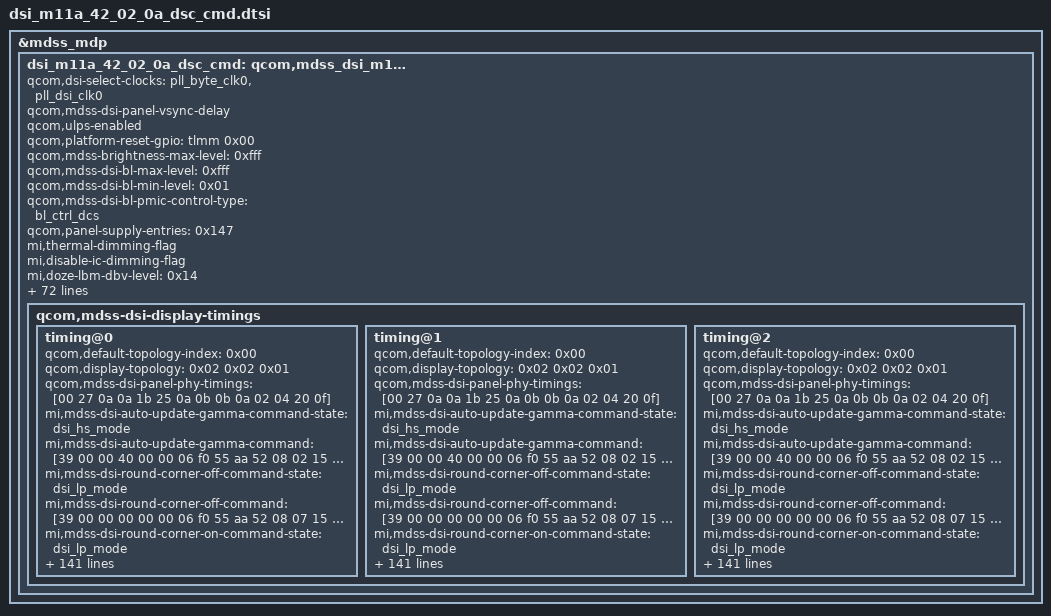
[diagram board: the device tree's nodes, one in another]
&mdss_mdp {
    dsi_m11a_42_02_0a_dsc_cmd: qcom,mdss_dsi_m11a_42_02_0a_dsc_cmd {
        qcom,dsi-select-clocks = "pll_byte_clk0", "pll_dsi_clk0";
        qcom,mdss-dsi-panel-vsync-delay;
        qcom,ulps-enabled;
        qcom,platform-reset-gpio = <&tlmm 0x00 0x00>;
        qcom,mdss-brightness-max-level = <0xfff>;
        qcom,mdss-dsi-bl-max-level = <0xfff>;
        qcom,mdss-dsi-bl-min-level = <0x01>;
        qcom,mdss-dsi-bl-pmic-control-type = "bl_ctrl_dcs";
        qcom,panel-supply-entries = <0x147>;
        mi,thermal-dimming-flag;
        mi,disable-ic-dimming-flag;
        mi,doze-lbm-dbv-level = <0x14>;
        mi,doze-hbm-dbv-level = <0xfc>;
        mi,need-fod-animal-in-normal-enabled;
        mi,fod-low-brightness-lux-threshold = <0x03>;
        mi,fod-low-brightness-clone-threshold = <0xc8>;
        mi,local-hbm-ui-ready-delay-num-frame = <0x04>;
        mi,local-hbm-ctrl-df-reg;
        mi,local-hbm-alpha-ctrl-aa-area;
        mi,local-hbm-white-110nit-update-flag;
        mi,local-hbm-white-1000nit-update-flag;
        mi,local-hbm-enabled;
        mi,mdss-dsi-panel-flatmode-on-status-value = <0x00>;
        mi,mdss-dsi-panel-flatmode-status-read-length = <0x01>;
        mi,mdss-dsi-panel-flatmode-status-read-command-state = "dsi_lp_mode";
        mi,mdss-dsi-panel-flatmode-status-read-command = <0x6010001 0x15f>;
        mi,flatmode-status-check-enabled;
        mi,flat-need-update-several-gamma;
        mi,flat-update-flag;
        mi,ddic-round-corner-enabled;
        mi,hbm-bl-max-level = <0x7ff>;
        mi,hbm-bl-min-level = <0x01>;
        mi,mdss-fac-brightness-max-level = <0x7ff>;
        mi,mdss-dsi-fac-bl-max-level = <0x7ff>;
        mi,normal-max-brightness-clone = <0x1fff>;
        mi,max-brightness-clone = <0x3fff>;
        mi,panel-id = <0x4d313141 0x420200>;
        mi,esd-err-irq-gpio = <&tlmm 0x74 0x2008>;
        qcom,mdss-dsi-dma-schedule-window = <0x32>;
        qcom,mdss-dsi-dma-schedule-line = <0x01>;
        qcom,mdss-dsi-panel-blackness-level = <0xc9e>;
        qcom,mdss-dsi-panel-peak-brightness = <0x401640>;
        qcom,mdss-dsi-panel-hdr-color-primaries = <0x38a4 0x3c8c 0x7d00 0x4268 0x3c8c 0x7530 0x1f40 0xbb8>;
        qcom,mdss-dsi-panel-hdr-enabled;
        qcom,bl-update-flag = "delay_until_first_frame";
        qcom,mdss-dsi-bl-inverted-dbv;
        qcom,mdss-dsi-lp11-init;
        qcom,mdss-dsi-tx-eot-append;
        qcom,mdss-dsi-te-using-te-pin;
        qcom,mdss-dsi-te-check-enable;
        qcom,mdss-dsi-te-dcs-command = <0x01>;
        qcom,mdss-dsi-wr-mem-continue = <0x3c>;
        qcom,mdss-dsi-wr-mem-start = <0x2c>;
        qcom,mdss-dsi-te-pin-select = <0x01>;
        qcom,mdss-pan-physical-height-dimension = <0x609>;
        qcom,mdss-pan-physical-width-dimension = <0x2b7>;
        qcom,mdss-dsi-reset-sequence = <0x01 0x0b 0x00 0x01 0x01 0x0b>;
        qcom,mdss-dsi-mdp-trigger = "none";
        qcom,mdss-dsi-dma-trigger = "trigger_sw";
        qcom,mdss-dsi-lane-3-state;
        qcom,mdss-dsi-lane-2-state;
        qcom,mdss-dsi-lane-1-state;
        qcom,mdss-dsi-lane-0-state;
        qcom,mdss-dsi-bllp-power-mode;
        qcom,mdss-dsi-bllp-eof-power-mode;
        qcom,mdss-dsi-lane-map = "lane_map_0123";
        qcom,mdss-dsi-traffic-mode = "burst_mode";
        qcom,dsi-phy-num = <0x00>;
        qcom,dsi-ctrl-num = <0x00>;
        qcom,mdss-dsi-border-color = <0x00>;
        qcom,mdss-dsi-underflow-color = <0xff>;
        qcom,mdss-dsi-color-order = "rgb_swap_rgb";
        qcom,mdss-dsi-bpp = <0x18>;
        qcom,mdss-dsi-stream = <0x00>;
        qcom,mdss-dsi-virtual-channel-id = <0x00>;
        qcom,mdss-dsi-panel-type = "dsi_cmd_mode";
        qcom,mdss-dsi-panel-name = "xiaomi 42 02 0a cmd mode dsc dsi panel";
    
        qcom,mdss-dsi-display-timings {
    
            timing@0 {
                qcom,default-topology-index = <0x00>;
                qcom,display-topology = <0x02 0x02 0x01>;
                qcom,mdss-dsi-panel-phy-timings = [00 27 0a 0a 1b 25 0a 0b 0b 0a 02 04 20 0f];
                mi,mdss-dsi-auto-update-gamma-command-state = "dsi_hs_mode";
                mi,mdss-dsi-auto-update-gamma-command = [39 00 00 40 00 00 06 f0 55 aa 52 08 02 15 00 00 00 00 00 02 cc 00];
                mi,mdss-dsi-round-corner-off-command-state = "dsi_lp_mode";
                mi,mdss-dsi-round-corner-off-command = [39 00 00 00 00 00 06 f0 55 aa 52 08 07 15 00 00 00 00 00 02 c0 b0];
                mi,mdss-dsi-round-corner-on-command-state = "dsi_lp_mode";
                mi,mdss-dsi-round-corner-on-command = [39 00 00 00 00 00 06 f0 55 aa 52 08 07 15 00 00 00 00 00 02 c0 b1];
                mi,mdss-dsi-local-hbm-off-to-hbm-command-state = "dsi_hs_mode";
                mi,mdss-dsi-local-hbm-off-to-hbm-command-update = <0x51 0x02 0x02>;
                mi,mdss-dsi-local-hbm-off-to-hbm-command = [39 00 00 40 00 00 06 f0 55 aa 52 08 02 15 00 00 00 00 00 02 cc 00 39 00 00 40 00 00 03 51 07 ff 39 00 00 40 00 00 02 86 00 39 00 00 00 00 00 02 87 20];
                mi,mdss-dsi-local-hbm-off-to-normal-command-state = "dsi_hs_mode";
                mi,mdss-dsi-local-hbm-off-to-normal-command-update = <0x51 0x02 0x02>;
                mi,mdss-dsi-local-hbm-off-to-normal-command = [39 00 00 40 00 00 06 f0 55 aa 52 08 02 15 00 00 00 00 00 02 cc 00 39 00 00 40 00 00 03 51 07 ff 39 00 00 40 00 00 02 86 00 39 00 00 00 00 00 02 87 20];
                mi,mdss-dsi-local-hbm-normal-green-500nit-command-state = "dsi_lp_mode";
                mi,mdss-dsi-local-hbm-normal-green-500nit-command-update = <0x87 0x1d 0x02 0xd0 0x1b 0x06 0xdf 0x19 0x02>;
                mi,mdss-dsi-local-hbm-normal-green-500nit-command = [39 00 00 40 00 00 06 f0 55 aa 52 08 02 15 00 00 00 00 00 02 cc 00 39 00 00 40 00 00 06 f0 55 aa 52 08 07 39 00 00 40 00 00 02 c0 b1 39 00 00 40 00 00 06 f0 55 aa 52 08 00 39 00 00 40 00 00 04 df 45 00 00 39 00 00 40 00 00 02 6f 13 39 00 00 40 00 00 05 df 02 d0 0b 42 39 00 00 40 00 00 02 6f 1b 39 00 00 40 00 00 05 df 02 54 0a c6 39 00 00 40 00 00 02 6f 1f 39 00 00 40 00 00 05 df 03 4c 0b be 39 00 00 40 00 00 02 6f 2b 39 00 00 40 00 00 07 df 3f ff 3f ff 3f ff 39 00 00 40 00 00 02 6f 32 39 00 00 40 00 00 07 df 00 00 13 00 00 00 39 00 00 40 00 00 02 6f 38 39 00 00 40 00 00 03 df 00 40 39 00 00 40 00 00 02 6f 88 39 00 00 40 00 00 02 df 40 39 00 00 40 00 00 02 6f 00 39 00 00 40 00 00 06 88 01 02 d0 0b 44 39 00 00 40 00 00 02 53 20 39 00 00 40 00 00 06 f0 55 aa 52 08 00 39 00 00 40 00 00 02 6f 4c 39 00 00 40 00 00 03 df 05 1c 39 00 00 40 00 00 06 f0 55 aa 52 08 02 39 00 00 40 00 00 07 d0 00 00 09 1a 00 00 39 00 00 40 00 00 02 6f 01 39 00 00 40 00 00 03 87 0d ff 39 00 00 40 00 00 02 87 21 39 00 00 00 00 00 02 85 00];
                mi,mdss-dsi-local-hbm-normal-white-110nit-command-state = "dsi_hs_mode";
                mi,mdss-dsi-local-hbm-normal-white-110nit-command-update = <0x87 0x1d 0x03 0xd0 0x1b 0x06>;
                mi,mdss-dsi-local-hbm-normal-white-110nit-command = [39 00 00 40 00 00 06 f0 55 aa 52 08 02 15 00 00 00 00 00 02 cc 00 39 00 00 40 00 00 06 f0 55 aa 52 08 07 39 00 00 40 00 00 02 c0 b1 39 00 00 40 00 00 06 f0 55 aa 52 08 00 39 00 00 40 00 00 04 df 45 00 00 39 00 00 40 00 00 02 6f 13 39 00 00 40 00 00 05 df 02 d0 0b 42 39 00 00 40 00 00 02 6f 1b 39 00 00 40 00 00 05 df 02 54 0a c6 39 00 00 40 00 00 02 6f 1f 39 00 00 40 00 00 05 df 03 4c 0b be 39 00 00 40 00 00 02 6f 2b 39 00 00 40 00 00 07 df 3f ff 3f ff 3f ff 39 00 00 40 00 00 02 6f 32 39 00 00 40 00 00 07 df 00 00 13 00 00 00 39 00 00 40 00 00 02 6f 38 39 00 00 40 00 00 03 df 00 40 39 00 00 40 00 00 02 6f 88 39 00 00 40 00 00 02 df 40 39 00 00 40 00 00 02 6f 00 39 00 00 40 00 00 06 88 01 02 d0 0b 44 39 00 00 40 00 00 02 53 20 39 00 00 40 00 00 06 f0 55 aa 52 08 00 39 00 00 40 00 00 02 6f 4c 39 00 00 40 00 00 03 df 05 1c 39 00 00 40 00 00 06 f0 55 aa 52 08 02 39 00 00 40 00 00 07 d0 08 00 07 26 08 7f 39 00 00 40 00 00 02 6f 01 39 00 00 40 00 00 03 87 0d ff 39 00 00 40 00 00 02 87 21 39 00 00 00 00 00 02 85 00];
                mi,mdss-dsi-local-hbm-hlpm-white-110nit-command-state = "dsi_hs_mode";
                mi,mdss-dsi-local-hbm-hlpm-white-110nit-command-update = <0x51 0x02 0x02 0x87 0x26 0x03 0xd0 0x24 0x06>;
                mi,mdss-dsi-local-hbm-hlpm-white-110nit-command = [39 00 00 40 00 00 06 f0 55 aa 52 08 02 15 00 00 40 00 00 02 cc 00 39 00 00 00 00 00 03 51 00 00 39 00 00 40 00 00 06 f0 55 aa 52 08 01 15 00 00 40 00 00 02 6f 02 15 00 00 40 00 00 02 b0 08 15 00 00 40 00 00 02 e4 80 15 00 00 40 00 00 02 6f 0a 15 00 00 40 00 00 02 e4 80 15 00 00 40 00 00 02 65 00 15 00 00 00 2a 00 02 38 00 39 00 00 40 00 00 06 f0 55 aa 52 08 07 15 00 00 40 00 00 02 c0 b1 39 00 00 40 00 00 06 f0 55 aa 52 08 00 39 00 00 40 00 00 04 df 45 00 00 15 00 00 40 00 00 02 6f 13 39 00 00 40 00 00 05 df 02 d0 0b 42 15 00 00 40 00 00 02 6f 1b 39 00 00 40 00 00 05 df 02 54 0a c6 15 00 00 40 00 00 02 6f 1f 39 00 00 40 00 00 05 df 03 4c 0b be 15 00 00 40 00 00 02 6f 2b 39 00 00 40 00 00 07 df 3f ff 3f ff 3f ff 15 00 00 40 00 00 02 6f 32 39 00 00 40 00 00 07 df 00 00 13 00 00 00 15 00 00 40 00 00 02 6f 38 39 00 00 40 00 00 03 df 00 40 15 00 00 40 00 00 02 6f 88 15 00 00 40 00 00 02 df 40 15 00 00 40 00 00 02 6f 00 39 00 00 40 00 00 06 88 01 02 d0 0b 44 15 00 00 40 00 00 02 53 20 39 00 00 40 00 00 06 f0 55 aa 52 08 00 15 00 00 40 00 00 02 6f 4c 39 00 00 40 00 00 03 df 05 1c 39 00 00 40 00 00 06 f0 55 aa 52 08 02 39 00 00 40 00 00 07 d0 08 00 07 26 08 7f 15 00 00 40 00 00 02 6f 01 39 00 00 40 00 00 03 87 0d ff 15 00 00 40 00 00 02 87 21 15 00 00 00 00 00 02 85 00];
                mi,mdss-dsi-local-hbm-normal-white-1000nit-command-state = "dsi_hs_mode";
                mi,mdss-dsi-local-hbm-normal-white-1000nit-command-update = <0x87 0x1d 0x02 0xd0 0x1b 0x06 0xdf 0x19 0x02>;
                mi,mdss-dsi-local-hbm-normal-white-1000nit-command = [39 00 00 40 00 00 06 f0 55 aa 52 08 02 15 00 00 00 00 00 02 cc 00 39 00 00 40 00 00 06 f0 55 aa 52 08 07 39 00 00 40 00 00 02 c0 b1 39 00 00 40 00 00 06 f0 55 aa 52 08 00 39 00 00 40 00 00 04 df 45 00 00 39 00 00 40 00 00 02 6f 13 39 00 00 40 00 00 05 df 02 d0 0b 42 39 00 00 40 00 00 02 6f 1b 39 00 00 40 00 00 05 df 02 54 0a c6 39 00 00 40 00 00 02 6f 1f 39 00 00 40 00 00 05 df 03 4c 0b be 39 00 00 40 00 00 02 6f 2b 39 00 00 40 00 00 07 df 3f ff 3f ff 3f ff 39 00 00 40 00 00 02 6f 32 39 00 00 40 00 00 07 df 00 00 13 00 00 00 39 00 00 40 00 00 02 6f 38 39 00 00 40 00 00 03 df 00 40 39 00 00 40 00 00 02 6f 88 39 00 00 40 00 00 02 df 40 39 00 00 40 00 00 02 6f 00 39 00 00 40 00 00 06 88 01 02 d0 0b 44 39 00 00 40 00 00 02 53 20 39 00 00 40 00 00 06 f0 55 aa 52 08 00 39 00 00 40 00 00 02 6f 4c 39 00 00 40 00 00 03 df 05 1c 39 00 00 40 00 00 06 f0 55 aa 52 08 02 39 00 00 40 00 00 07 d0 0b 06 09 97 0b 69 39 00 00 40 00 00 02 6f 01 39 00 00 40 00 00 03 87 0d ff 39 00 00 40 00 00 02 87 21 39 00 00 00 00 00 02 85 00];
                mi,mdss-dsi-local-hbm-hlpm-white-1000nit-command-state = "dsi_hs_mode";
                mi,mdss-dsi-local-hbm-hlpm-white-1000nit-command-update = <0x51 0x02 0x02 0x87 0x26 0x02 0xd0 0x24 0x06 0xdf 0x22 0x02>;
                mi,mdss-dsi-local-hbm-hlpm-white-1000nit-command = [39 00 00 40 00 00 06 f0 55 aa 52 08 02 15 00 00 40 00 00 02 cc 00 39 00 00 00 00 00 03 51 00 00 39 00 00 40 00 00 06 f0 55 aa 52 08 01 15 00 00 40 00 00 02 6f 02 15 00 00 40 00 00 02 b0 08 15 00 00 40 00 00 02 e4 80 15 00 00 40 00 00 02 6f 0a 15 00 00 40 00 00 02 e4 80 15 00 00 40 00 00 02 65 00 15 00 00 00 2a 00 02 38 00 39 00 00 40 00 00 06 f0 55 aa 52 08 07 15 00 00 40 00 00 02 c0 b1 39 00 00 40 00 00 06 f0 55 aa 52 08 00 39 00 00 40 00 00 04 df 45 00 00 15 00 00 40 00 00 02 6f 13 39 00 00 40 00 00 05 df 02 d0 0b 42 15 00 00 40 00 00 02 6f 1b 39 00 00 40 00 00 05 df 02 54 0a c6 15 00 00 40 00 00 02 6f 1f 39 00 00 40 00 00 05 df 03 4c 0b be 15 00 00 40 00 00 02 6f 2b 39 00 00 40 00 00 07 df 3f ff 3f ff 3f ff 15 00 00 40 00 00 02 6f 32 39 00 00 40 00 00 07 df 00 00 13 00 00 00 15 00 00 40 00 00 02 6f 38 39 00 00 40 00 00 03 df 00 40 15 00 00 40 00 00 02 6f 88 15 00 00 40 00 00 02 df 40 15 00 00 40 00 00 02 6f 00 39 00 00 40 00 00 06 88 01 02 d0 0b 44 15 00 00 40 00 00 02 53 20 39 00 00 40 00 00 06 f0 55 aa 52 08 00 15 00 00 40 00 00 02 6f 4c 39 00 00 40 00 00 03 df 05 1c 39 00 00 40 00 00 06 f0 55 aa 52 08 02 39 00 00 40 00 00 07 d0 0b 06 09 97 0b 69 15 00 00 40 00 00 02 6f 01 39 00 00 40 00 00 03 87 0d ff 15 00 00 40 00 00 02 87 21 15 00 00 00 00 00 02 85 00];
                mi,mdss-dsi-hbm-fod-off-command-update = <0x51 0x00 0x02>;
                mi,mdss-dsi-hbm-fod-off-command-state = "dsi_lp_mode";
                mi,mdss-dsi-hbm-fod-off-command = <0x39000040 0x6f0 0x55aa5208 0x2150000 0x02 0xcc003900 0x00 0x35107ff>;
                mi,mdss-dsi-hbm-fod-on-command-state = "dsi_lp_mode";
                mi,mdss-dsi-hbm-fod-on-command = <0x39000040 0x6f0 0x55aa5208 0x2150000 0x02 0xcc003900 0x00 0x3510fff>;
                mi,mdss-dsi-local-hbm-off-to-llpm-command-state = "dsi_hs_mode";
                mi,mdss-dsi-local-hbm-off-to-llpm-command = [39 00 00 40 00 00 06 f0 55 aa 52 08 02 15 00 00 00 00 00 02 cc 00 39 00 00 40 00 00 03 51 07 ff 39 00 00 40 00 00 02 86 00 39 00 00 00 00 00 02 87 20 39 00 00 40 00 00 06 f0 55 aa 52 08 00 15 00 00 40 00 00 02 6f 01 15 00 00 00 00 00 02 be 41 39 00 00 40 00 00 07 51 00 00 00 00 01 55 39 00 00 40 00 00 06 f0 55 aa 52 08 01 39 00 00 40 00 00 02 6f 02 39 00 00 40 00 00 02 b0 00 39 00 00 40 00 00 02 e4 90 39 00 00 40 00 00 02 6f 0a 39 00 00 40 00 00 02 e4 90 39 00 00 40 00 00 02 39 00 39 00 00 00 00 00 02 65 01];
                mi,mdss-dsi-local-hbm-off-to-hlpm-command-state = "dsi_hs_mode";
                mi,mdss-dsi-local-hbm-off-to-hlpm-command = [39 00 00 40 00 00 06 f0 55 aa 52 08 02 15 00 00 00 00 00 02 cc 00 39 00 00 40 00 00 03 51 07 ff 39 00 00 40 00 00 02 86 00 39 00 00 00 00 00 02 87 20 39 00 00 40 00 00 06 f0 55 aa 52 08 00 15 00 00 40 00 00 02 6f 01 15 00 00 00 00 00 02 be 41 39 00 00 40 00 00 07 51 00 00 00 00 0f ff 39 00 00 40 00 00 06 f0 55 aa 52 08 01 39 00 00 40 00 00 02 6f 02 39 00 00 40 00 00 02 b0 00 39 00 00 40 00 00 02 e4 90 39 00 00 40 00 00 02 6f 0a 39 00 00 40 00 00 02 e4 90 39 00 00 40 00 00 02 39 00 39 00 00 00 00 00 02 65 01];
                mi,mdss-dsi-doze-lbm-nolp-command-state = "dsi_hs_mode";
                mi,mdss-dsi-doze-lbm-nolp-command = [39 00 00 40 00 00 06 f0 55 aa 52 08 02 15 00 00 00 00 00 02 cc 00 39 00 00 40 00 00 03 51 00 14 39 00 00 40 00 00 06 f0 55 aa 52 08 01 15 00 00 40 00 00 02 6f 02 15 00 00 40 00 00 02 b0 08 15 00 00 40 00 00 02 e4 80 15 00 00 40 00 00 02 6f 0a 15 00 00 40 00 00 02 e4 80 15 00 00 40 00 00 02 65 00 05 00 00 00 00 00 01 38 39 00 00 40 00 00 06 f0 55 aa 52 08 00 39 00 00 40 00 00 02 6f 01 39 00 00 00 00 00 02 be 45];
                mi,mdss-dsi-doze-hbm-nolp-command-state = "dsi_hs_mode";
                mi,mdss-dsi-doze-hbm-nolp-command = [39 00 00 40 00 00 06 f0 55 aa 52 08 02 15 00 00 00 00 00 02 cc 00 39 00 00 40 00 00 03 51 00 fc 39 00 00 40 00 00 06 f0 55 aa 52 08 01 15 00 00 40 00 00 02 6f 02 15 00 00 40 00 00 02 b0 08 15 00 00 40 00 00 02 e4 80 15 00 00 40 00 00 02 6f 0a 15 00 00 40 00 00 02 e4 80 15 00 00 40 00 00 02 65 00 05 00 00 00 00 00 01 38 39 00 00 40 00 00 06 f0 55 aa 52 08 00 39 00 00 40 00 00 02 6f 01 39 00 00 00 00 00 02 be 45];
                mi,mdss-dsi-doze-lbm-command-state = "dsi_hs_mode";
                mi,mdss-dsi-doze-lbm-command = [39 00 00 40 00 00 06 f0 55 aa 52 08 02 15 00 00 00 00 00 02 cc 00 39 00 00 40 00 00 06 f0 55 aa 52 08 00 15 00 00 40 00 00 02 6f 01 15 00 00 00 00 00 02 be 41 39 00 00 40 00 00 07 51 00 00 00 00 01 55 39 00 00 40 00 00 06 f0 55 aa 52 08 01 15 00 00 40 00 00 02 6f 02 15 00 00 40 00 00 02 b0 00 15 00 00 40 00 00 02 e4 90 15 00 00 40 00 00 02 6f 0a 15 00 00 40 00 00 02 e4 90 05 00 00 40 00 00 01 39 15 00 00 00 00 00 02 65 01];
                mi,mdss-dsi-doze-hbm-command-state = "dsi_hs_mode";
                mi,mdss-dsi-doze-hbm-command = [39 00 00 40 00 00 06 f0 55 aa 52 08 02 15 00 00 00 00 00 02 cc 00 39 00 00 40 00 00 06 f0 55 aa 52 08 00 15 00 00 40 00 00 02 6f 01 15 00 00 00 00 00 02 be 41 39 00 00 40 00 00 07 51 00 00 00 00 0f ff 39 00 00 40 00 00 06 f0 55 aa 52 08 01 15 00 00 40 00 00 02 6f 02 15 00 00 40 00 00 02 b0 00 15 00 00 40 00 00 02 e4 90 15 00 00 40 00 00 02 6f 0a 15 00 00 40 00 00 02 e4 90 05 00 00 40 00 00 01 39 15 00 00 00 00 00 02 65 01];
                mi,mdss-dsi-flat-mode-off-sec-command-state = "dsi_hs_mode";
                mi,mdss-dsi-flat-mode-off-sec-command = [39 00 00 40 00 00 06 f0 55 aa 52 08 02 15 00 00 00 00 00 02 cc 00];
                mi,mdss-dsi-flat-mode-off-command-state = "dsi_hs_mode";
                mi,mdss-dsi-flat-mode-off-command = <0x15000040 0x22f 0x2150000 0x40000002 0x5f011500 0x400000 0x2260015 0x4000 0x28b00 0x39000040 0x6f0 0x55aa5208 0x150000 0x40000002 0x6f031500 0x400000 0x2c01015 0x4000 0x26f31 0x15000040 0x2df 0x21390000 0x40000006 0xf055aa52 0x8021500 0x400000 0x2cc3015 0x14 0x2ce01>;
                mi,mdss-dsi-flat-mode-on-sec-command-state = "dsi_hs_mode";
                mi,mdss-dsi-flat-mode-on-sec-command = [39 00 00 40 00 00 06 f0 55 aa 52 08 02 15 00 00 00 00 00 02 cc 00];
                mi,mdss-dsi-flat-mode-on-command-state = "dsi_hs_mode";
                mi,mdss-dsi-flat-mode-on-command = <0x15000040 0x22f 0x2150000 0x40000002 0x5f001500 0x400000 0x2260215 0x4000 0x28b00 0x39000040 0x6f0 0x55aa5208 0x150000 0x40000002 0x6f031500 0x400000 0x2c03215 0x4000 0x26f31 0x15000040 0x2df 0x23390000 0x40000006 0xf055aa52 0x8021500 0x400000 0x2cc3015 0x14 0x2ce01>;
                mi,mdss-flat-status-control-lhbm-gamma-cfg = <0x23 0x21>;
                mi,mdss-flat-status-control-gamma-cfg = <0x32 0x10>;
                qcom,mdss-dsc-block-prediction-enable;
                qcom,mdss-dsc-bit-per-pixel = <0x08>;
                qcom,mdss-dsc-bit-per-component = <0x0a>;
                qcom,mdss-dsc-slice-per-pkt = <0x02>;
                qcom,mdss-dsc-slice-width = <0x2d0>;
                qcom,mdss-dsc-slice-height = <0x20>;
                qcom,mdss-dsc-scr-version = <0x00>;
                qcom,mdss-dsc-version = <0x12>;
                qcom,compression-mode = "dsc";
                qcom,mdss-dsi-nolp-command-state = "dsi_hs_mode";
                qcom,mdss-dsi-nolp-command = [39 00 00 40 00 00 06 f0 55 aa 52 08 02 15 00 00 00 00 00 02 cc 00 39 00 00 40 00 00 03 51 00 00 39 00 00 40 00 00 06 f0 55 aa 52 08 01 15 00 00 40 00 00 02 6f 02 15 00 00 40 00 00 02 b0 08 15 00 00 40 00 00 02 e4 80 15 00 00 40 00 00 02 6f 0a 15 00 00 40 00 00 02 e4 80 15 00 00 40 00 00 02 65 00 05 00 00 00 00 00 01 38 39 00 00 40 00 00 06 f0 55 aa 52 08 00 39 00 00 40 00 00 02 6f 01 39 00 00 00 00 00 02 be 45];
                qcom,mdss-dsi-timing-switch-command-state = "dsi_hs_mode";
                qcom,mdss-dsi-timing-switch-command-update = <0xc0 0x04 0x01 0xdf 0x06 0x01>;
                qcom,mdss-dsi-timing-switch-command = [15 00 00 40 00 00 02 2f 02 15 00 00 40 00 00 02 8b 00 39 00 00 40 00 00 06 f0 55 aa 52 08 00 15 00 00 40 00 00 02 6f 03 15 00 00 40 00 00 02 c0 10 15 00 00 40 00 00 02 6f 31 15 00 00 40 00 00 02 df 21 39 00 00 40 00 00 06 f0 55 aa 52 08 02 15 00 00 40 00 00 02 cc 30 15 00 00 00 00 00 02 ce 01];
                qcom,mdss-dsi-off-command-state = "dsi_lp_mode";
                qcom,mdss-dsi-on-command-state = "dsi_lp_mode";
                qcom,mdss-dsi-off-command = [39 00 00 00 14 00 02 28 00 39 00 00 00 64 00 02 10 00];
                qcom,mdss-dsi-on-command = [39 00 00 40 00 00 06 f0 55 aa 52 08 00 15 00 00 40 00 00 02 6f 1a 15 00 00 00 00 00 02 c2 00 39 00 00 40 00 00 06 f0 55 aa 52 08 01 15 00 00 40 00 00 02 6f 0e 15 00 00 40 00 00 02 b4 1f 39 00 00 40 00 00 05 ff aa 55 a5 80 15 00 00 40 00 00 02 6f 02 15 00 00 00 00 00 02 f5 10 39 00 00 40 00 00 06 f0 55 aa 52 08 01 39 00 00 00 00 00 03 b1 06 06 39 00 00 40 00 00 06 f0 55 aa 52 08 01 15 00 00 40 00 00 02 6f 01 15 00 00 40 00 00 02 c4 e3 39 00 00 40 00 00 05 ff aa 55 a5 80 15 00 00 40 00 00 02 6f 18 15 00 00 00 00 00 02 f8 19 39 00 00 40 00 00 06 f0 55 aa 52 08 01 15 00 00 40 00 00 02 6f 01 39 00 00 00 00 00 04 c5 0b 0b 0b 39 00 00 40 00 00 06 f0 55 aa 52 08 04 15 00 00 00 00 00 02 c0 20 39 00 00 40 00 00 06 f0 55 aa 52 08 00 15 00 00 40 00 00 02 6f 20 39 00 00 40 00 00 09 c6 55 55 55 55 55 55 55 55 39 00 00 40 00 00 05 ff aa 55 a5 80 15 00 00 40 00 00 02 6f 1b 15 00 00 40 00 00 02 f4 55 15 00 00 40 00 00 02 6f 19 15 00 00 00 00 00 02 f2 00 39 00 00 40 00 00 05 ff aa 55 a5 81 15 00 00 40 00 00 02 6f 18 15 00 00 00 00 00 02 fb 04 39 00 00 40 00 00 05 ff aa 55 a5 81 15 00 00 40 00 00 02 6f 07 15 00 00 00 00 00 02 fc 08 39 00 00 40 00 00 05 2a 00 00 05 9f 39 00 00 00 00 00 05 2b 00 00 0c 7f 15 00 00 40 00 00 02 90 03 39 00 00 00 00 00 13 91 ab a8 00 20 d2 00 02 86 03 5e 00 0a 03 5b 02 63 10 f0 15 00 00 40 00 00 02 35 00 15 00 00 00 00 00 02 5a 01 39 00 00 40 00 00 06 f0 55 aa 52 08 01 39 00 00 40 00 00 06 d2 00 00 00 00 15 15 00 00 40 00 00 02 6f 05 39 00 00 40 00 00 04 d2 01 00 00 15 00 00 40 00 00 02 6f 0e 39 00 00 40 00 00 06 d2 00 00 10 13 32 39 00 00 40 00 00 0b e4 80 03 00 00 00 00 00 00 00 33 15 00 00 40 00 00 02 6f 0a 39 00 00 00 00 00 07 e4 80 03 00 10 00 53 39 00 00 40 00 00 05 3b 00 18 00 10 15 00 00 40 00 00 02 53 20 39 00 00 40 00 00 07 51 00 00 0f ff 0f ff 15 00 00 40 00 00 02 9c 01 15 00 00 00 00 00 02 2c 00 15 00 00 40 00 00 02 2f 02 15 00 00 40 00 00 02 5f 01 15 00 00 40 00 00 02 26 00 15 00 00 40 00 00 02 8b 00 39 00 00 40 00 00 06 f0 55 aa 52 08 00 15 00 00 40 00 00 02 6f 03 15 00 00 40 00 00 02 c0 10 15 00 00 40 00 00 02 6f 31 15 00 00 40 00 00 02 df 21 39 00 00 40 00 00 06 f0 55 aa 52 08 02 15 00 00 40 00 00 02 cc 30 15 00 00 40 14 00 02 ce 01 15 00 00 00 00 00 02 cc 00 39 00 00 40 00 00 06 f0 55 aa 52 08 01 39 00 00 40 00 00 0c c3 90 04 20 13 ff 00 04 20 0e ff 00 15 00 00 40 00 00 02 6f 0b 39 00 00 40 00 00 07 c3 06 30 1d 06 67 14 15 00 00 40 00 00 02 6f 11 39 00 00 40 00 00 07 c3 06 30 1d 06 67 14 15 00 00 40 00 00 02 6f 17 39 00 00 40 00 00 07 c3 06 30 1d 06 67 14 15 00 00 40 00 00 02 6f 1d 39 00 00 40 00 00 07 c3 06 30 1d 06 67 14 15 00 00 40 00 00 02 6f 23 39 00 00 00 00 00 07 c3 06 30 1d 06 67 14 39 00 00 40 00 00 06 f0 55 aa 52 08 00 15 00 00 40 00 00 02 6f 01 15 00 00 00 00 00 02 be 45 15 00 00 40 00 00 02 6f 05 15 00 00 00 00 00 02 be 88 39 00 00 40 00 00 06 f0 55 aa 52 08 00 15 00 00 40 00 00 02 6f 07 39 00 00 40 00 00 05 b5 2a 1e 00 32 39 00 00 40 00 00 1a b7 40 40 41 42 43 44 45 46 47 48 49 4a 4b 4c 4d 4e 4f 50 51 51 51 51 51 51 51 15 00 00 40 00 00 02 6f 19 39 00 00 40 00 00 0d b7 17 88 99 aa bb cc dd ee ff ff ff ff 15 00 00 40 00 00 02 6f 25 39 00 00 00 00 00 19 b7 ba ff 77 ef 67 df 57 cf 47 bf 37 af 27 9f 17 8f 07 7f ff ff ff ff ff ff 39 00 00 40 00 00 06 f0 55 aa 52 08 07 15 00 00 00 00 00 02 c0 b1 05 00 00 00 78 00 02 11 00 05 00 00 00 00 00 02 29 00 39 00 00 40 00 00 06 f0 55 aa 52 08 04 15 00 00 40 00 00 02 6f 16 15 00 00 40 00 00 02 d2 19 15 00 00 40 00 00 02 6f 16 15 00 00 40 00 00 02 d4 18 15 00 00 40 00 00 02 6f 2f 15 00 00 40 00 00 02 d2 28 15 00 00 40 00 00 02 6f 2f 15 00 00 40 00 00 02 d4 27 15 00 00 40 00 00 02 6f 48 15 00 00 40 00 00 02 d2 18 15 00 00 40 00 00 02 6f 48 15 00 00 00 00 00 02 d4 17];
                qcom,mdss-mdp-transfer-time-us = <0x1c84>;
                qcom,mdss-dsi-panel-jitter = <0x05 0x01>;
                qcom,mdss-dsi-panel-clockrate = <0x47868c00>;
                qcom,mdss-dsi-v-bottom-border = <0x00>;
                qcom,mdss-dsi-v-top-border = <0x00>;
                qcom,mdss-dsi-h-right-border = <0x00>;
                qcom,mdss-dsi-h-left-border = <0x00>;
                qcom,mdss-dsi-h-sync-pulse = <0x00>;
                qcom,mdss-dsi-v-pulse-width = <0x0e>;
                qcom,mdss-dsi-v-front-porch = <0x10>;
                qcom,mdss-dsi-v-back-porch = <0x06>;
                qcom,mdss-dsi-h-sync-skew = <0x00>;
                qcom,mdss-dsi-h-pulse-width = <0x0c>;
                qcom,mdss-dsi-h-back-porch = <0x08>;
                qcom,mdss-dsi-h-front-porch = <0x08>;
                qcom,mdss-dsi-panel-height = <0xc80>;
                qcom,mdss-dsi-panel-width = <0x5a0>;
                qcom,mdss-dsi-panel-framerate = <0x3c>;
                qcom,mdss-dsi-cmd-mode;
            };
    
            timing@1 {
                qcom,default-topology-index = <0x00>;
                qcom,display-topology = <0x02 0x02 0x01>;
                qcom,mdss-dsi-panel-phy-timings = [00 27 0a 0a 1b 25 0a 0b 0b 0a 02 04 20 0f];
                mi,mdss-dsi-auto-update-gamma-command-state = "dsi_hs_mode";
                mi,mdss-dsi-auto-update-gamma-command = [39 00 00 40 00 00 06 f0 55 aa 52 08 02 15 00 00 00 00 00 02 cc 00];
                mi,mdss-dsi-round-corner-off-command-state = "dsi_lp_mode";
                mi,mdss-dsi-round-corner-off-command = [39 00 00 00 00 00 06 f0 55 aa 52 08 07 15 00 00 00 00 00 02 c0 b0];
                mi,mdss-dsi-round-corner-on-command-state = "dsi_lp_mode";
                mi,mdss-dsi-round-corner-on-command = [39 00 00 00 00 00 06 f0 55 aa 52 08 07 15 00 00 00 00 00 02 c0 b1];
                mi,mdss-dsi-local-hbm-off-to-hbm-command-state = "dsi_hs_mode";
                mi,mdss-dsi-local-hbm-off-to-hbm-command-update = <0x51 0x02 0x02>;
                mi,mdss-dsi-local-hbm-off-to-hbm-command = [39 00 00 40 00 00 06 f0 55 aa 52 08 02 15 00 00 00 00 00 02 cc 00 39 00 00 40 00 00 03 51 07 ff 39 00 00 40 00 00 02 86 00 39 00 00 00 00 00 02 87 20];
                mi,mdss-dsi-local-hbm-off-to-normal-command-state = "dsi_hs_mode";
                mi,mdss-dsi-local-hbm-off-to-normal-command-update = <0x51 0x02 0x02>;
                mi,mdss-dsi-local-hbm-off-to-normal-command = [39 00 00 40 00 00 06 f0 55 aa 52 08 02 15 00 00 00 00 00 02 cc 00 39 00 00 40 00 00 03 51 07 ff 39 00 00 40 00 00 02 86 00 39 00 00 00 00 00 02 87 20];
                mi,mdss-dsi-local-hbm-normal-green-500nit-command-state = "dsi_lp_mode";
                mi,mdss-dsi-local-hbm-normal-green-500nit-command-update = <0x87 0x1d 0x02 0xd0 0x1b 0x06 0xdf 0x19 0x02>;
                mi,mdss-dsi-local-hbm-normal-green-500nit-command = [39 00 00 40 00 00 06 f0 55 aa 52 08 02 15 00 00 00 00 00 02 cc 00 39 00 00 40 00 00 06 f0 55 aa 52 08 07 39 00 00 40 00 00 02 c0 b1 39 00 00 40 00 00 06 f0 55 aa 52 08 00 39 00 00 40 00 00 04 df 45 00 00 39 00 00 40 00 00 02 6f 13 39 00 00 40 00 00 05 df 02 d0 0b 42 39 00 00 40 00 00 02 6f 1b 39 00 00 40 00 00 05 df 02 54 0a c6 39 00 00 40 00 00 02 6f 1f 39 00 00 40 00 00 05 df 03 4c 0b be 39 00 00 40 00 00 02 6f 2b 39 00 00 40 00 00 07 df 3f ff 3f ff 3f ff 39 00 00 40 00 00 02 6f 32 39 00 00 40 00 00 07 df 00 00 13 00 00 00 39 00 00 40 00 00 02 6f 38 39 00 00 40 00 00 03 df 00 40 39 00 00 40 00 00 02 6f 88 39 00 00 40 00 00 02 df 40 39 00 00 40 00 00 02 6f 00 39 00 00 40 00 00 06 88 01 02 d0 0b 44 39 00 00 40 00 00 02 53 20 39 00 00 40 00 00 06 f0 55 aa 52 08 00 39 00 00 40 00 00 02 6f 4c 39 00 00 40 00 00 03 df 05 1c 39 00 00 40 00 00 06 f0 55 aa 52 08 02 39 00 00 40 00 00 07 d0 00 00 09 1a 00 00 39 00 00 40 00 00 02 6f 01 39 00 00 40 00 00 03 87 0d ff 39 00 00 40 00 00 02 87 21 39 00 00 00 00 00 02 85 00];
                mi,mdss-dsi-local-hbm-normal-white-110nit-command-state = "dsi_hs_mode";
                mi,mdss-dsi-local-hbm-normal-white-110nit-command-update = <0x87 0x1d 0x03 0xd0 0x1b 0x06>;
                mi,mdss-dsi-local-hbm-normal-white-110nit-command = [39 00 00 40 00 00 06 f0 55 aa 52 08 02 15 00 00 00 00 00 02 cc 00 39 00 00 40 00 00 06 f0 55 aa 52 08 07 39 00 00 40 00 00 02 c0 b1 39 00 00 40 00 00 06 f0 55 aa 52 08 00 39 00 00 40 00 00 04 df 45 00 00 39 00 00 40 00 00 02 6f 13 39 00 00 40 00 00 05 df 02 d0 0b 42 39 00 00 40 00 00 02 6f 1b 39 00 00 40 00 00 05 df 02 54 0a c6 39 00 00 40 00 00 02 6f 1f 39 00 00 40 00 00 05 df 03 4c 0b be 39 00 00 40 00 00 02 6f 2b 39 00 00 40 00 00 07 df 3f ff 3f ff 3f ff 39 00 00 40 00 00 02 6f 32 39 00 00 40 00 00 07 df 00 00 13 00 00 00 39 00 00 40 00 00 02 6f 38 39 00 00 40 00 00 03 df 00 40 39 00 00 40 00 00 02 6f 88 39 00 00 40 00 00 02 df 40 39 00 00 40 00 00 02 6f 00 39 00 00 40 00 00 06 88 01 02 d0 0b 44 39 00 00 40 00 00 02 53 20 39 00 00 40 00 00 06 f0 55 aa 52 08 00 39 00 00 40 00 00 02 6f 4c 39 00 00 40 00 00 03 df 05 1c 39 00 00 40 00 00 06 f0 55 aa 52 08 02 39 00 00 40 00 00 07 d0 08 00 07 26 08 7f 39 00 00 40 00 00 02 6f 01 39 00 00 40 00 00 03 87 0d ff 39 00 00 40 00 00 02 87 21 39 00 00 00 00 00 02 85 00];
                mi,mdss-dsi-local-hbm-hlpm-white-110nit-command-state = "dsi_hs_mode";
                mi,mdss-dsi-local-hbm-hlpm-white-110nit-command-update = <0x51 0x02 0x02 0x87 0x26 0x03 0xd0 0x24 0x06>;
                mi,mdss-dsi-local-hbm-hlpm-white-110nit-command = [39 00 00 40 00 00 06 f0 55 aa 52 08 02 15 00 00 40 00 00 02 cc 00 39 00 00 00 00 00 03 51 00 00 39 00 00 40 00 00 06 f0 55 aa 52 08 01 15 00 00 40 00 00 02 6f 02 15 00 00 40 00 00 02 b0 08 15 00 00 40 00 00 02 e4 80 15 00 00 40 00 00 02 6f 0a 15 00 00 40 00 00 02 e4 80 15 00 00 40 00 00 02 65 00 15 00 00 00 2a 00 02 38 00 39 00 00 40 00 00 06 f0 55 aa 52 08 07 15 00 00 40 00 00 02 c0 b1 39 00 00 40 00 00 06 f0 55 aa 52 08 00 39 00 00 40 00 00 04 df 45 00 00 15 00 00 40 00 00 02 6f 13 39 00 00 40 00 00 05 df 02 d0 0b 42 15 00 00 40 00 00 02 6f 1b 39 00 00 40 00 00 05 df 02 54 0a c6 15 00 00 40 00 00 02 6f 1f 39 00 00 40 00 00 05 df 03 4c 0b be 15 00 00 40 00 00 02 6f 2b 39 00 00 40 00 00 07 df 3f ff 3f ff 3f ff 15 00 00 40 00 00 02 6f 32 39 00 00 40 00 00 07 df 00 00 13 00 00 00 15 00 00 40 00 00 02 6f 38 39 00 00 40 00 00 03 df 00 40 15 00 00 40 00 00 02 6f 88 15 00 00 40 00 00 02 df 40 15 00 00 40 00 00 02 6f 00 39 00 00 40 00 00 06 88 01 02 d0 0b 44 15 00 00 40 00 00 02 53 20 39 00 00 40 00 00 06 f0 55 aa 52 08 00 15 00 00 40 00 00 02 6f 4c 39 00 00 40 00 00 03 df 05 1c 39 00 00 40 00 00 06 f0 55 aa 52 08 02 39 00 00 40 00 00 07 d0 08 00 07 26 08 7f 15 00 00 40 00 00 02 6f 01 39 00 00 40 00 00 03 87 0d ff 15 00 00 40 00 00 02 87 21 15 00 00 00 00 00 02 85 00];
                mi,mdss-dsi-local-hbm-normal-white-1000nit-command-state = "dsi_hs_mode";
                mi,mdss-dsi-local-hbm-normal-white-1000nit-command-update = <0x87 0x1d 0x02 0xd0 0x1b 0x06 0xdf 0x19 0x02>;
                mi,mdss-dsi-local-hbm-normal-white-1000nit-command = [39 00 00 40 00 00 06 f0 55 aa 52 08 02 15 00 00 00 00 00 02 cc 00 39 00 00 40 00 00 06 f0 55 aa 52 08 07 39 00 00 40 00 00 02 c0 b1 39 00 00 40 00 00 06 f0 55 aa 52 08 00 39 00 00 40 00 00 04 df 45 00 00 39 00 00 40 00 00 02 6f 13 39 00 00 40 00 00 05 df 02 d0 0b 42 39 00 00 40 00 00 02 6f 1b 39 00 00 40 00 00 05 df 02 54 0a c6 39 00 00 40 00 00 02 6f 1f 39 00 00 40 00 00 05 df 03 4c 0b be 39 00 00 40 00 00 02 6f 2b 39 00 00 40 00 00 07 df 3f ff 3f ff 3f ff 39 00 00 40 00 00 02 6f 32 39 00 00 40 00 00 07 df 00 00 13 00 00 00 39 00 00 40 00 00 02 6f 38 39 00 00 40 00 00 03 df 00 40 39 00 00 40 00 00 02 6f 88 39 00 00 40 00 00 02 df 40 39 00 00 40 00 00 02 6f 00 39 00 00 40 00 00 06 88 01 02 d0 0b 44 39 00 00 40 00 00 02 53 20 39 00 00 40 00 00 06 f0 55 aa 52 08 00 39 00 00 40 00 00 02 6f 4c 39 00 00 40 00 00 03 df 05 1c 39 00 00 40 00 00 06 f0 55 aa 52 08 02 39 00 00 40 00 00 07 d0 0b 06 09 97 0b 69 39 00 00 40 00 00 02 6f 01 39 00 00 40 00 00 03 87 0d ff 39 00 00 40 00 00 02 87 21 39 00 00 00 00 00 02 85 00];
                mi,mdss-dsi-local-hbm-hlpm-white-1000nit-command-state = "dsi_hs_mode";
                mi,mdss-dsi-local-hbm-hlpm-white-1000nit-command-update = <0x51 0x02 0x02 0x87 0x26 0x02 0xd0 0x24 0x06 0xdf 0x22 0x02>;
                mi,mdss-dsi-local-hbm-hlpm-white-1000nit-command = [39 00 00 40 00 00 06 f0 55 aa 52 08 02 15 00 00 40 00 00 02 cc 00 39 00 00 00 00 00 03 51 00 00 39 00 00 40 00 00 06 f0 55 aa 52 08 01 15 00 00 40 00 00 02 6f 02 15 00 00 40 00 00 02 b0 08 15 00 00 40 00 00 02 e4 80 15 00 00 40 00 00 02 6f 0a 15 00 00 40 00 00 02 e4 80 15 00 00 40 00 00 02 65 00 15 00 00 00 2a 00 02 38 00 39 00 00 40 00 00 06 f0 55 aa 52 08 07 15 00 00 40 00 00 02 c0 b1 39 00 00 40 00 00 06 f0 55 aa 52 08 00 39 00 00 40 00 00 04 df 45 00 00 15 00 00 40 00 00 02 6f 13 39 00 00 40 00 00 05 df 02 d0 0b 42 15 00 00 40 00 00 02 6f 1b 39 00 00 40 00 00 05 df 02 54 0a c6 15 00 00 40 00 00 02 6f 1f 39 00 00 40 00 00 05 df 03 4c 0b be 15 00 00 40 00 00 02 6f 2b 39 00 00 40 00 00 07 df 3f ff 3f ff 3f ff 15 00 00 40 00 00 02 6f 32 39 00 00 40 00 00 07 df 00 00 13 00 00 00 15 00 00 40 00 00 02 6f 38 39 00 00 40 00 00 03 df 00 40 15 00 00 40 00 00 02 6f 88 15 00 00 40 00 00 02 df 40 15 00 00 40 00 00 02 6f 00 39 00 00 40 00 00 06 88 01 02 d0 0b 44 15 00 00 40 00 00 02 53 20 39 00 00 40 00 00 06 f0 55 aa 52 08 00 15 00 00 40 00 00 02 6f 4c 39 00 00 40 00 00 03 df 05 1c 39 00 00 40 00 00 06 f0 55 aa 52 08 02 39 00 00 40 00 00 07 d0 0b 06 09 97 0b 69 15 00 00 40 00 00 02 6f 01 39 00 00 40 00 00 03 87 0d ff 15 00 00 40 00 00 02 87 21 15 00 00 00 00 00 02 85 00];
                mi,mdss-dsi-hbm-fod-off-command-update = <0x51 0x00 0x02>;
                mi,mdss-dsi-hbm-fod-off-command-state = "dsi_lp_mode";
                mi,mdss-dsi-hbm-fod-off-command = <0x39000040 0x6f0 0x55aa5208 0x2150000 0x02 0xcc003900 0x00 0x35107ff>;
                mi,mdss-dsi-hbm-fod-on-command-state = "dsi_lp_mode";
                mi,mdss-dsi-hbm-fod-on-command = <0x39000040 0x6f0 0x55aa5208 0x2150000 0x02 0xcc003900 0x00 0x3510fff>;
                mi,mdss-dsi-local-hbm-off-to-llpm-command-state = "dsi_hs_mode";
                mi,mdss-dsi-local-hbm-off-to-llpm-command = [39 00 00 40 00 00 06 f0 55 aa 52 08 02 15 00 00 00 00 00 02 cc 00 39 00 00 40 00 00 03 51 07 ff 39 00 00 40 00 00 02 86 00 39 00 00 00 00 00 02 87 20 39 00 00 40 00 00 06 f0 55 aa 52 08 00 15 00 00 40 00 00 02 6f 01 15 00 00 00 00 00 02 be 41 39 00 00 40 00 00 07 51 00 00 00 00 01 55 39 00 00 40 00 00 06 f0 55 aa 52 08 01 39 00 00 40 00 00 02 6f 02 39 00 00 40 00 00 02 b0 00 39 00 00 40 00 00 02 e4 90 39 00 00 40 00 00 02 6f 0a 39 00 00 40 00 00 02 e4 90 39 00 00 40 00 00 02 39 00 39 00 00 00 00 00 02 65 01];
                mi,mdss-dsi-local-hbm-off-to-hlpm-command-state = "dsi_hs_mode";
                mi,mdss-dsi-local-hbm-off-to-hlpm-command = [39 00 00 40 00 00 06 f0 55 aa 52 08 02 15 00 00 00 00 00 02 cc 00 39 00 00 40 00 00 03 51 07 ff 39 00 00 40 00 00 02 86 00 39 00 00 00 00 00 02 87 20 39 00 00 40 00 00 06 f0 55 aa 52 08 00 15 00 00 40 00 00 02 6f 01 15 00 00 00 00 00 02 be 41 39 00 00 40 00 00 07 51 00 00 00 00 0f ff 39 00 00 40 00 00 06 f0 55 aa 52 08 01 39 00 00 40 00 00 02 6f 02 39 00 00 40 00 00 02 b0 00 39 00 00 40 00 00 02 e4 90 39 00 00 40 00 00 02 6f 0a 39 00 00 40 00 00 02 e4 90 39 00 00 40 00 00 02 39 00 39 00 00 00 00 00 02 65 01];
                mi,mdss-dsi-doze-lbm-nolp-command-state = "dsi_hs_mode";
                mi,mdss-dsi-doze-lbm-nolp-command = [39 00 00 40 00 00 06 f0 55 aa 52 08 02 15 00 00 00 00 00 02 cc 00 39 00 00 40 00 00 03 51 00 14 39 00 00 40 00 00 06 f0 55 aa 52 08 01 15 00 00 40 00 00 02 6f 02 15 00 00 40 00 00 02 b0 08 15 00 00 40 00 00 02 e4 80 15 00 00 40 00 00 02 6f 0a 15 00 00 40 00 00 02 e4 80 15 00 00 40 00 00 02 65 00 05 00 00 00 00 00 01 38 39 00 00 40 00 00 06 f0 55 aa 52 08 00 39 00 00 40 00 00 02 6f 01 39 00 00 00 00 00 02 be 45];
                mi,mdss-dsi-doze-hbm-nolp-command-state = "dsi_hs_mode";
                mi,mdss-dsi-doze-hbm-nolp-command = [39 00 00 40 00 00 06 f0 55 aa 52 08 02 15 00 00 00 00 00 02 cc 00 39 00 00 40 00 00 03 51 00 fc 39 00 00 40 00 00 06 f0 55 aa 52 08 01 15 00 00 40 00 00 02 6f 02 15 00 00 40 00 00 02 b0 08 15 00 00 40 00 00 02 e4 80 15 00 00 40 00 00 02 6f 0a 15 00 00 40 00 00 02 e4 80 15 00 00 40 00 00 02 65 00 05 00 00 00 00 00 01 38 39 00 00 40 00 00 06 f0 55 aa 52 08 00 39 00 00 40 00 00 02 6f 01 39 00 00 00 00 00 02 be 45];
                mi,mdss-dsi-doze-lbm-command-state = "dsi_hs_mode";
                mi,mdss-dsi-doze-lbm-command = [39 00 00 40 00 00 06 f0 55 aa 52 08 02 15 00 00 00 00 00 02 cc 00 39 00 00 40 00 00 06 f0 55 aa 52 08 00 15 00 00 40 00 00 02 6f 01 15 00 00 00 00 00 02 be 41 39 00 00 40 00 00 07 51 00 00 00 00 01 55 39 00 00 40 00 00 06 f0 55 aa 52 08 01 15 00 00 40 00 00 02 6f 02 15 00 00 40 00 00 02 b0 00 15 00 00 40 00 00 02 e4 90 15 00 00 40 00 00 02 6f 0a 15 00 00 40 00 00 02 e4 90 05 00 00 40 00 00 01 39 15 00 00 00 00 00 02 65 01];
                mi,mdss-dsi-doze-hbm-command-state = "dsi_hs_mode";
                mi,mdss-dsi-doze-hbm-command = [39 00 00 40 00 00 06 f0 55 aa 52 08 02 15 00 00 00 00 00 02 cc 00 39 00 00 40 00 00 06 f0 55 aa 52 08 00 15 00 00 40 00 00 02 6f 01 15 00 00 00 00 00 02 be 41 39 00 00 40 00 00 07 51 00 00 00 00 0f ff 39 00 00 40 00 00 06 f0 55 aa 52 08 01 15 00 00 40 00 00 02 6f 02 15 00 00 40 00 00 02 b0 00 15 00 00 40 00 00 02 e4 90 15 00 00 40 00 00 02 6f 0a 15 00 00 40 00 00 02 e4 90 05 00 00 40 00 00 01 39 15 00 00 00 00 00 02 65 01];
                mi,mdss-dsi-flat-mode-off-sec-command-state = "dsi_hs_mode";
                mi,mdss-dsi-flat-mode-off-sec-command = [39 00 00 40 00 00 06 f0 55 aa 52 08 02 15 00 00 00 00 00 02 cc 00];
                mi,mdss-dsi-flat-mode-off-command-state = "dsi_hs_mode";
                mi,mdss-dsi-flat-mode-off-command = <0x15000040 0x22f 0x1150000 0x40000002 0x5f011500 0x400000 0x2260015 0x4000 0x28b10 0x39000040 0x6f0 0x55aa5208 0x150000 0x40000002 0x6f031500 0x400000 0x2c01015 0x4000 0x26f31 0x15000040 0x2df 0x20390000 0x40000006 0xf055aa52 0x8021500 0x400000 0x2cc3015 0x14 0x2ce01>;
                mi,mdss-dsi-flat-mode-on-sec-command-state = "dsi_hs_mode";
                mi,mdss-dsi-flat-mode-on-sec-command = [39 00 00 40 00 00 06 f0 55 aa 52 08 02 15 00 00 00 00 00 02 cc 00];
                mi,mdss-dsi-flat-mode-on-command-state = "dsi_hs_mode";
                mi,mdss-dsi-flat-mode-on-command = <0x15000040 0x22f 0x1150000 0x40000002 0x5f001500 0x400000 0x2260215 0x4000 0x28b10 0x39000040 0x6f0 0x55aa5208 0x150000 0x40000002 0x6f031500 0x400000 0x2c03215 0x4000 0x26f31 0x15000040 0x2df 0x22390000 0x40000006 0xf055aa52 0x8021500 0x400000 0x2cc3015 0x14 0x2ce01>;
                mi,mdss-flat-status-control-lhbm-gamma-cfg = <0x22 0x20>;
                mi,mdss-flat-status-control-gamma-cfg = <0x32 0x10>;
                qcom,mdss-dsc-block-prediction-enable;
                qcom,mdss-dsc-bit-per-pixel = <0x08>;
                qcom,mdss-dsc-bit-per-component = <0x0a>;
                qcom,mdss-dsc-slice-per-pkt = <0x02>;
                qcom,mdss-dsc-slice-width = <0x2d0>;
                qcom,mdss-dsc-slice-height = <0x20>;
                qcom,mdss-dsc-scr-version = <0x00>;
                qcom,mdss-dsc-version = <0x12>;
                qcom,compression-mode = "dsc";
                qcom,mdss-dsi-nolp-command-state = "dsi_hs_mode";
                qcom,mdss-dsi-nolp-command = [39 00 00 40 00 00 06 f0 55 aa 52 08 02 15 00 00 00 00 00 02 cc 00 39 00 00 40 00 00 03 51 00 00 39 00 00 40 00 00 06 f0 55 aa 52 08 01 15 00 00 40 00 00 02 6f 02 15 00 00 40 00 00 02 b0 08 15 00 00 40 00 00 02 e4 80 15 00 00 40 00 00 02 6f 0a 15 00 00 40 00 00 02 e4 80 15 00 00 40 00 00 02 65 00 05 00 00 00 00 00 01 38 39 00 00 40 00 00 06 f0 55 aa 52 08 00 39 00 00 40 00 00 02 6f 01 39 00 00 00 00 00 02 be 45];
                qcom,mdss-dsi-timing-switch-command-state = "dsi_hs_mode";
                qcom,mdss-dsi-timing-switch-command-update = <0xc0 0x04 0x01 0xdf 0x06 0x01>;
                qcom,mdss-dsi-timing-switch-command = [15 00 00 40 00 00 02 2f 01 15 00 00 40 00 00 02 8b 10 39 00 00 40 00 00 06 f0 55 aa 52 08 00 15 00 00 40 00 00 02 6f 03 15 00 00 40 00 00 02 c0 10 15 00 00 40 00 00 02 6f 31 15 00 00 40 00 00 02 df 20 39 00 00 40 00 00 06 f0 55 aa 52 08 02 15 00 00 40 00 00 02 cc 30 15 00 00 00 00 00 02 ce 01];
                qcom,mdss-dsi-off-command-state = "dsi_lp_mode";
                qcom,mdss-dsi-on-command-state = "dsi_lp_mode";
                qcom,mdss-dsi-off-command = [39 00 00 00 14 00 02 28 00 39 00 00 00 64 00 02 10 00];
                qcom,mdss-dsi-on-command = [39 00 00 40 00 00 06 f0 55 aa 52 08 00 15 00 00 40 00 00 02 6f 1a 15 00 00 00 00 00 02 c2 00 39 00 00 40 00 00 06 f0 55 aa 52 08 01 15 00 00 40 00 00 02 6f 0e 15 00 00 40 00 00 02 b4 1f 39 00 00 40 00 00 05 ff aa 55 a5 80 15 00 00 40 00 00 02 6f 02 15 00 00 00 00 00 02 f5 10 39 00 00 40 00 00 06 f0 55 aa 52 08 01 39 00 00 00 00 00 03 b1 06 06 39 00 00 40 00 00 06 f0 55 aa 52 08 01 15 00 00 40 00 00 02 6f 01 15 00 00 40 00 00 02 c4 e3 39 00 00 40 00 00 05 ff aa 55 a5 80 15 00 00 40 00 00 02 6f 18 15 00 00 00 00 00 02 f8 19 39 00 00 40 00 00 06 f0 55 aa 52 08 01 15 00 00 40 00 00 02 6f 01 39 00 00 40 00 00 04 c5 0b 0b 0b 39 00 00 40 00 00 06 f0 55 aa 52 08 04 15 00 00 00 00 00 02 c0 20 39 00 00 40 00 00 06 f0 55 aa 52 08 00 15 00 00 40 00 00 02 6f 20 39 00 00 40 00 00 09 c6 55 55 55 55 55 55 55 55 39 00 00 40 00 00 05 ff aa 55 a5 80 15 00 00 40 00 00 02 6f 1b 15 00 00 00 00 00 02 f4 55 15 00 00 40 00 00 02 6f 19 15 00 00 00 00 00 02 f2 00 39 00 00 40 00 00 05 ff aa 55 a5 81 15 00 00 40 00 00 02 6f 18 15 00 00 00 00 00 02 fb 04 39 00 00 40 00 00 05 ff aa 55 a5 81 15 00 00 40 00 00 02 6f 07 15 00 00 00 00 00 02 fc 08 39 00 00 40 00 00 05 2a 00 00 05 9f 39 00 00 00 00 00 05 2b 00 00 0c 7f 15 00 00 40 00 00 02 90 03 39 00 00 00 00 00 13 91 ab a8 00 20 d2 00 02 86 03 5e 00 0a 03 5b 02 63 10 f0 15 00 00 40 00 00 02 35 00 15 00 00 00 00 00 02 5a 01 39 00 00 40 00 00 06 f0 55 aa 52 08 01 39 00 00 40 00 00 06 d2 00 00 00 00 15 15 00 00 40 00 00 02 6f 05 39 00 00 40 00 00 04 d2 01 00 00 15 00 00 40 00 00 02 6f 0e 39 00 00 40 00 00 06 d2 00 00 10 13 32 39 00 00 40 00 00 0b e4 80 03 00 00 00 00 00 00 00 33 15 00 00 40 00 00 02 6f 0a 39 00 00 00 00 00 07 e4 80 03 00 10 00 53 39 00 00 00 00 00 05 3b 00 18 00 10 15 00 00 40 00 00 02 53 20 39 00 00 40 00 00 07 51 00 00 0f ff 0f ff 15 00 00 40 00 00 02 9c 01 15 00 00 00 00 00 02 2c 00 15 00 00 40 00 00 02 2f 01 15 00 00 40 00 00 02 5f 01 15 00 00 40 00 00 02 26 00 15 00 00 40 00 00 02 8b 10 39 00 00 40 00 00 06 f0 55 aa 52 08 00 15 00 00 40 00 00 02 6f 03 15 00 00 40 00 00 02 c0 10 15 00 00 40 00 00 02 6f 31 15 00 00 40 00 00 02 df 20 39 00 00 40 00 00 06 f0 55 aa 52 08 02 15 00 00 40 00 00 02 cc 30 15 00 00 40 14 00 02 ce 01 15 00 00 00 00 00 02 cc 00 39 00 00 40 00 00 06 f0 55 aa 52 08 01 39 00 00 40 00 00 0c c3 90 04 20 13 ff 00 04 20 0e ff 00 15 00 00 40 00 00 02 6f 0b 39 00 00 40 00 00 07 c3 06 30 1d 06 67 14 15 00 00 40 00 00 02 6f 11 39 00 00 40 00 00 07 c3 06 30 1d 06 67 14 15 00 00 40 00 00 02 6f 17 39 00 00 40 00 00 07 c3 06 30 1d 06 67 14 15 00 00 40 00 00 02 6f 1d 39 00 00 40 00 00 07 c3 06 30 1d 06 67 14 15 00 00 40 00 00 02 6f 23 39 00 00 00 00 00 07 c3 06 30 1d 06 67 14 39 00 00 40 00 00 06 f0 55 aa 52 08 00 15 00 00 40 00 00 02 6f 01 15 00 00 00 00 00 02 be 45 15 00 00 40 00 00 02 6f 05 15 00 00 00 00 00 02 be 88 39 00 00 40 00 00 06 f0 55 aa 52 08 00 15 00 00 40 00 00 02 6f 07 39 00 00 40 00 00 05 b5 2a 1e 00 32 39 00 00 40 00 00 1a b7 40 40 41 42 43 44 45 46 47 48 49 4a 4b 4c 4d 4e 4f 50 51 51 51 51 51 51 51 15 00 00 40 00 00 02 6f 19 39 00 00 40 00 00 0d b7 17 88 99 aa bb cc dd ee ff ff ff ff 15 00 00 40 00 00 02 6f 25 39 00 00 00 00 00 19 b7 ba ff 77 ef 67 df 57 cf 47 bf 37 af 27 9f 17 8f 07 7f ff ff ff ff ff ff 39 00 00 40 00 00 06 f0 55 aa 52 08 07 15 00 00 00 00 00 02 c0 b1 05 00 00 00 78 00 02 11 00 05 00 00 00 00 00 02 29 00 39 00 00 40 00 00 06 f0 55 aa 52 08 04 15 00 00 40 00 00 02 6f 16 15 00 00 40 00 00 02 d2 19 15 00 00 40 00 00 02 6f 16 15 00 00 40 00 00 02 d4 18 15 00 00 40 00 00 02 6f 2f 15 00 00 40 00 00 02 d2 28 15 00 00 40 00 00 02 6f 2f 15 00 00 40 00 00 02 d4 27 15 00 00 40 00 00 02 6f 48 15 00 00 40 00 00 02 d2 18 15 00 00 40 00 00 02 6f 48 15 00 00 00 00 00 02 d4 17];
                qcom,mdss-mdp-transfer-time-us = <0x1c84>;
                qcom,mdss-dsi-panel-jitter = <0x05 0x01>;
                qcom,mdss-dsi-panel-clockrate = <0x47868c00>;
                qcom,mdss-dsi-v-bottom-border = <0x00>;
                qcom,mdss-dsi-v-top-border = <0x00>;
                qcom,mdss-dsi-h-right-border = <0x00>;
                qcom,mdss-dsi-h-left-border = <0x00>;
                qcom,mdss-dsi-h-sync-pulse = <0x00>;
                qcom,mdss-dsi-v-pulse-width = <0x0e>;
                qcom,mdss-dsi-v-front-porch = <0x10>;
                qcom,mdss-dsi-v-back-porch = <0x06>;
                qcom,mdss-dsi-h-sync-skew = <0x00>;
                qcom,mdss-dsi-h-pulse-width = <0x0c>;
                qcom,mdss-dsi-h-back-porch = <0x08>;
                qcom,mdss-dsi-h-front-porch = <0x08>;
                qcom,mdss-dsi-panel-height = <0xc80>;
                qcom,mdss-dsi-panel-width = <0x5a0>;
                qcom,mdss-dsi-panel-framerate = <0x5a>;
                qcom,mdss-dsi-cmd-mode;
            };
    
            timing@2 {
                qcom,default-topology-index = <0x00>;
                qcom,display-topology = <0x02 0x02 0x01>;
                qcom,mdss-dsi-panel-phy-timings = [00 27 0a 0a 1b 25 0a 0b 0b 0a 02 04 20 0f];
                mi,mdss-dsi-auto-update-gamma-command-state = "dsi_hs_mode";
                mi,mdss-dsi-auto-update-gamma-command = [39 00 00 40 00 00 06 f0 55 aa 52 08 02 15 00 00 00 00 00 02 cc 00];
                mi,mdss-dsi-round-corner-off-command-state = "dsi_lp_mode";
                mi,mdss-dsi-round-corner-off-command = [39 00 00 00 00 00 06 f0 55 aa 52 08 07 15 00 00 00 00 00 02 c0 b0];
                mi,mdss-dsi-round-corner-on-command-state = "dsi_lp_mode";
                mi,mdss-dsi-round-corner-on-command = [39 00 00 00 00 00 06 f0 55 aa 52 08 07 15 00 00 00 00 00 02 c0 b1];
                mi,mdss-dsi-local-hbm-off-to-hbm-command-state = "dsi_hs_mode";
                mi,mdss-dsi-local-hbm-off-to-hbm-command-update = <0x51 0x02 0x02>;
                mi,mdss-dsi-local-hbm-off-to-hbm-command = [39 00 00 40 00 00 06 f0 55 aa 52 08 02 15 00 00 00 00 00 02 cc 00 39 00 00 40 00 00 03 51 07 ff 39 00 00 40 00 00 02 86 00 39 00 00 00 00 00 02 87 20];
                mi,mdss-dsi-local-hbm-off-to-normal-command-state = "dsi_hs_mode";
                mi,mdss-dsi-local-hbm-off-to-normal-command-update = <0x51 0x02 0x02>;
                mi,mdss-dsi-local-hbm-off-to-normal-command = [39 00 00 40 00 00 06 f0 55 aa 52 08 02 15 00 00 00 00 00 02 cc 00 39 00 00 40 00 00 03 51 07 ff 39 00 00 40 00 00 02 86 00 39 00 00 00 00 00 02 87 20];
                mi,mdss-dsi-local-hbm-normal-green-500nit-command-state = "dsi_lp_mode";
                mi,mdss-dsi-local-hbm-normal-green-500nit-command-update = <0x87 0x1d 0x02 0xd0 0x1b 0x06 0xdf 0x19 0x02>;
                mi,mdss-dsi-local-hbm-normal-green-500nit-command = [39 00 00 40 00 00 06 f0 55 aa 52 08 02 15 00 00 00 00 00 02 cc 00 39 00 00 40 00 00 06 f0 55 aa 52 08 07 39 00 00 40 00 00 02 c0 b1 39 00 00 40 00 00 06 f0 55 aa 52 08 00 39 00 00 40 00 00 04 df 45 00 00 39 00 00 40 00 00 02 6f 13 39 00 00 40 00 00 05 df 02 d0 0b 42 39 00 00 40 00 00 02 6f 1b 39 00 00 40 00 00 05 df 02 54 0a c6 39 00 00 40 00 00 02 6f 1f 39 00 00 40 00 00 05 df 03 4c 0b be 39 00 00 40 00 00 02 6f 2b 39 00 00 40 00 00 07 df 3f ff 3f ff 3f ff 39 00 00 40 00 00 02 6f 32 39 00 00 40 00 00 07 df 00 00 13 00 00 00 39 00 00 40 00 00 02 6f 38 39 00 00 40 00 00 03 df 00 40 39 00 00 40 00 00 02 6f 88 39 00 00 40 00 00 02 df 40 39 00 00 40 00 00 02 6f 00 39 00 00 40 00 00 06 88 01 02 d0 0b 44 39 00 00 40 00 00 02 53 20 39 00 00 40 00 00 06 f0 55 aa 52 08 00 39 00 00 40 00 00 02 6f 4c 39 00 00 40 00 00 03 df 05 1c 39 00 00 40 00 00 06 f0 55 aa 52 08 02 39 00 00 40 00 00 07 d0 00 00 09 1a 00 00 39 00 00 40 00 00 02 6f 01 39 00 00 40 00 00 03 87 0d ff 39 00 00 40 00 00 02 87 21 39 00 00 00 00 00 02 85 00];
                mi,mdss-dsi-local-hbm-normal-white-110nit-command-state = "dsi_hs_mode";
                mi,mdss-dsi-local-hbm-normal-white-110nit-command-update = <0x87 0x1d 0x03 0xd0 0x1b 0x06>;
                mi,mdss-dsi-local-hbm-normal-white-110nit-command = [39 00 00 40 00 00 06 f0 55 aa 52 08 02 15 00 00 00 00 00 02 cc 00 39 00 00 40 00 00 06 f0 55 aa 52 08 07 39 00 00 40 00 00 02 c0 b1 39 00 00 40 00 00 06 f0 55 aa 52 08 00 39 00 00 40 00 00 04 df 45 00 00 39 00 00 40 00 00 02 6f 13 39 00 00 40 00 00 05 df 02 d0 0b 42 39 00 00 40 00 00 02 6f 1b 39 00 00 40 00 00 05 df 02 54 0a c6 39 00 00 40 00 00 02 6f 1f 39 00 00 40 00 00 05 df 03 4c 0b be 39 00 00 40 00 00 02 6f 2b 39 00 00 40 00 00 07 df 3f ff 3f ff 3f ff 39 00 00 40 00 00 02 6f 32 39 00 00 40 00 00 07 df 00 00 13 00 00 00 39 00 00 40 00 00 02 6f 38 39 00 00 40 00 00 03 df 00 40 39 00 00 40 00 00 02 6f 88 39 00 00 40 00 00 02 df 40 39 00 00 40 00 00 02 6f 00 39 00 00 40 00 00 06 88 01 02 d0 0b 44 39 00 00 40 00 00 02 53 20 39 00 00 40 00 00 06 f0 55 aa 52 08 00 39 00 00 40 00 00 02 6f 4c 39 00 00 40 00 00 03 df 05 1c 39 00 00 40 00 00 06 f0 55 aa 52 08 02 39 00 00 40 00 00 07 d0 08 00 07 26 08 7f 39 00 00 40 00 00 02 6f 01 39 00 00 40 00 00 03 87 0d ff 39 00 00 40 00 00 02 87 21 39 00 00 00 00 00 02 85 00];
                mi,mdss-dsi-local-hbm-hlpm-white-110nit-command-state = "dsi_hs_mode";
                mi,mdss-dsi-local-hbm-hlpm-white-110nit-command-update = <0x51 0x02 0x02 0x87 0x26 0x03 0xd0 0x24 0x06>;
                mi,mdss-dsi-local-hbm-hlpm-white-110nit-command = [39 00 00 40 00 00 06 f0 55 aa 52 08 02 15 00 00 40 00 00 02 cc 00 39 00 00 00 00 00 03 51 00 00 39 00 00 40 00 00 06 f0 55 aa 52 08 01 15 00 00 40 00 00 02 6f 02 15 00 00 40 00 00 02 b0 08 15 00 00 40 00 00 02 e4 80 15 00 00 40 00 00 02 6f 0a 15 00 00 40 00 00 02 e4 80 15 00 00 40 00 00 02 65 00 15 00 00 00 2a 00 02 38 00 39 00 00 40 00 00 06 f0 55 aa 52 08 07 15 00 00 40 00 00 02 c0 b1 39 00 00 40 00 00 06 f0 55 aa 52 08 00 39 00 00 40 00 00 04 df 45 00 00 15 00 00 40 00 00 02 6f 13 39 00 00 40 00 00 05 df 02 d0 0b 42 15 00 00 40 00 00 02 6f 1b 39 00 00 40 00 00 05 df 02 54 0a c6 15 00 00 40 00 00 02 6f 1f 39 00 00 40 00 00 05 df 03 4c 0b be 15 00 00 40 00 00 02 6f 2b 39 00 00 40 00 00 07 df 3f ff 3f ff 3f ff 15 00 00 40 00 00 02 6f 32 39 00 00 40 00 00 07 df 00 00 13 00 00 00 15 00 00 40 00 00 02 6f 38 39 00 00 40 00 00 03 df 00 40 15 00 00 40 00 00 02 6f 88 15 00 00 40 00 00 02 df 40 15 00 00 40 00 00 02 6f 00 39 00 00 40 00 00 06 88 01 02 d0 0b 44 15 00 00 40 00 00 02 53 20 39 00 00 40 00 00 06 f0 55 aa 52 08 00 15 00 00 40 00 00 02 6f 4c 39 00 00 40 00 00 03 df 05 1c 39 00 00 40 00 00 06 f0 55 aa 52 08 02 39 00 00 40 00 00 07 d0 08 00 07 26 08 7f 15 00 00 40 00 00 02 6f 01 39 00 00 40 00 00 03 87 0d ff 15 00 00 40 00 00 02 87 21 15 00 00 00 00 00 02 85 00];
                mi,mdss-dsi-local-hbm-normal-white-1000nit-command-state = "dsi_hs_mode";
                mi,mdss-dsi-local-hbm-normal-white-1000nit-command-update = <0x87 0x1d 0x02 0xd0 0x1b 0x06 0xdf 0x19 0x02>;
                mi,mdss-dsi-local-hbm-normal-white-1000nit-command = [39 00 00 40 00 00 06 f0 55 aa 52 08 02 15 00 00 00 00 00 02 cc 00 39 00 00 40 00 00 06 f0 55 aa 52 08 07 39 00 00 40 00 00 02 c0 b1 39 00 00 40 00 00 06 f0 55 aa 52 08 00 39 00 00 40 00 00 04 df 45 00 00 39 00 00 40 00 00 02 6f 13 39 00 00 40 00 00 05 df 02 d0 0b 42 39 00 00 40 00 00 02 6f 1b 39 00 00 40 00 00 05 df 02 54 0a c6 39 00 00 40 00 00 02 6f 1f 39 00 00 40 00 00 05 df 03 4c 0b be 39 00 00 40 00 00 02 6f 2b 39 00 00 40 00 00 07 df 3f ff 3f ff 3f ff 39 00 00 40 00 00 02 6f 32 39 00 00 40 00 00 07 df 00 00 13 00 00 00 39 00 00 40 00 00 02 6f 38 39 00 00 40 00 00 03 df 00 40 39 00 00 40 00 00 02 6f 88 39 00 00 40 00 00 02 df 40 39 00 00 40 00 00 02 6f 00 39 00 00 40 00 00 06 88 01 02 d0 0b 44 39 00 00 40 00 00 02 53 20 39 00 00 40 00 00 06 f0 55 aa 52 08 00 39 00 00 40 00 00 02 6f 4c 39 00 00 40 00 00 03 df 05 1c 39 00 00 40 00 00 06 f0 55 aa 52 08 02 39 00 00 40 00 00 07 d0 0b 06 09 97 0b 69 39 00 00 40 00 00 02 6f 01 39 00 00 40 00 00 03 87 0d ff 39 00 00 40 00 00 02 87 21 39 00 00 00 00 00 02 85 00];
                mi,mdss-dsi-local-hbm-hlpm-white-1000nit-command-state = "dsi_hs_mode";
                mi,mdss-dsi-local-hbm-hlpm-white-1000nit-command-update = <0x51 0x02 0x02 0x87 0x26 0x02 0xd0 0x24 0x06 0xdf 0x22 0x02>;
                mi,mdss-dsi-local-hbm-hlpm-white-1000nit-command = [39 00 00 40 00 00 06 f0 55 aa 52 08 02 15 00 00 40 00 00 02 cc 00 39 00 00 00 00 00 03 51 00 00 39 00 00 40 00 00 06 f0 55 aa 52 08 01 15 00 00 40 00 00 02 6f 02 15 00 00 40 00 00 02 b0 08 15 00 00 40 00 00 02 e4 80 15 00 00 40 00 00 02 6f 0a 15 00 00 40 00 00 02 e4 80 15 00 00 40 00 00 02 65 00 15 00 00 00 2a 00 02 38 00 39 00 00 40 00 00 06 f0 55 aa 52 08 07 15 00 00 40 00 00 02 c0 b1 39 00 00 40 00 00 06 f0 55 aa 52 08 00 39 00 00 40 00 00 04 df 45 00 00 15 00 00 40 00 00 02 6f 13 39 00 00 40 00 00 05 df 02 d0 0b 42 15 00 00 40 00 00 02 6f 1b 39 00 00 40 00 00 05 df 02 54 0a c6 15 00 00 40 00 00 02 6f 1f 39 00 00 40 00 00 05 df 03 4c 0b be 15 00 00 40 00 00 02 6f 2b 39 00 00 40 00 00 07 df 3f ff 3f ff 3f ff 15 00 00 40 00 00 02 6f 32 39 00 00 40 00 00 07 df 00 00 13 00 00 00 15 00 00 40 00 00 02 6f 38 39 00 00 40 00 00 03 df 00 40 15 00 00 40 00 00 02 6f 88 15 00 00 40 00 00 02 df 40 15 00 00 40 00 00 02 6f 00 39 00 00 40 00 00 06 88 01 02 d0 0b 44 15 00 00 40 00 00 02 53 20 39 00 00 40 00 00 06 f0 55 aa 52 08 00 15 00 00 40 00 00 02 6f 4c 39 00 00 40 00 00 03 df 05 1c 39 00 00 40 00 00 06 f0 55 aa 52 08 02 39 00 00 40 00 00 07 d0 0b 06 09 97 0b 69 15 00 00 40 00 00 02 6f 01 39 00 00 40 00 00 03 87 0d ff 15 00 00 40 00 00 02 87 21 15 00 00 00 00 00 02 85 00];
                mi,mdss-dsi-hbm-fod-off-command-update = <0x51 0x00 0x02>;
                mi,mdss-dsi-hbm-fod-off-command-state = "dsi_lp_mode";
                mi,mdss-dsi-hbm-fod-off-command = <0x39000040 0x6f0 0x55aa5208 0x2150000 0x02 0xcc003900 0x00 0x35107ff>;
                mi,mdss-dsi-hbm-fod-on-command-state = "dsi_lp_mode";
                mi,mdss-dsi-hbm-fod-on-command = <0x39000040 0x6f0 0x55aa5208 0x2150000 0x02 0xcc003900 0x00 0x3510fff>;
                mi,mdss-dsi-local-hbm-off-to-llpm-command-state = "dsi_hs_mode";
                mi,mdss-dsi-local-hbm-off-to-llpm-command = [39 00 00 40 00 00 06 f0 55 aa 52 08 02 15 00 00 00 00 00 02 cc 00 39 00 00 40 00 00 03 51 07 ff 39 00 00 40 00 00 02 86 00 39 00 00 00 00 00 02 87 20 39 00 00 40 00 00 06 f0 55 aa 52 08 00 15 00 00 40 00 00 02 6f 01 15 00 00 00 00 00 02 be 41 39 00 00 40 00 00 07 51 00 00 00 00 01 55 39 00 00 40 00 00 06 f0 55 aa 52 08 01 39 00 00 40 00 00 02 6f 02 39 00 00 40 00 00 02 b0 00 39 00 00 40 00 00 02 e4 90 39 00 00 40 00 00 02 6f 0a 39 00 00 40 00 00 02 e4 90 39 00 00 40 00 00 02 39 00 39 00 00 00 00 00 02 65 01];
                mi,mdss-dsi-local-hbm-off-to-hlpm-command-state = "dsi_hs_mode";
                mi,mdss-dsi-local-hbm-off-to-hlpm-command = [39 00 00 40 00 00 06 f0 55 aa 52 08 02 15 00 00 00 00 00 02 cc 00 39 00 00 40 00 00 03 51 07 ff 39 00 00 40 00 00 02 86 00 39 00 00 00 00 00 02 87 20 39 00 00 40 00 00 06 f0 55 aa 52 08 00 15 00 00 40 00 00 02 6f 01 15 00 00 00 00 00 02 be 41 39 00 00 40 00 00 07 51 00 00 00 00 0f ff 39 00 00 40 00 00 06 f0 55 aa 52 08 01 39 00 00 40 00 00 02 6f 02 39 00 00 40 00 00 02 b0 00 39 00 00 40 00 00 02 e4 90 39 00 00 40 00 00 02 6f 0a 39 00 00 40 00 00 02 e4 90 39 00 00 40 00 00 02 39 00 39 00 00 00 00 00 02 65 01];
                mi,mdss-dsi-doze-lbm-nolp-command-state = "dsi_hs_mode";
                mi,mdss-dsi-doze-lbm-nolp-command = [39 00 00 40 00 00 06 f0 55 aa 52 08 02 15 00 00 00 00 00 02 cc 00 39 00 00 40 00 00 03 51 00 14 39 00 00 40 00 00 06 f0 55 aa 52 08 01 15 00 00 40 00 00 02 6f 02 15 00 00 40 00 00 02 b0 08 15 00 00 40 00 00 02 e4 80 15 00 00 40 00 00 02 6f 0a 15 00 00 40 00 00 02 e4 80 15 00 00 40 00 00 02 65 00 05 00 00 00 00 00 01 38 39 00 00 40 00 00 06 f0 55 aa 52 08 00 39 00 00 40 00 00 02 6f 01 39 00 00 00 00 00 02 be 45];
                mi,mdss-dsi-doze-hbm-nolp-command-state = "dsi_hs_mode";
                mi,mdss-dsi-doze-hbm-nolp-command = [39 00 00 40 00 00 06 f0 55 aa 52 08 02 15 00 00 00 00 00 02 cc 00 39 00 00 40 00 00 03 51 00 fc 39 00 00 40 00 00 06 f0 55 aa 52 08 01 15 00 00 40 00 00 02 6f 02 15 00 00 40 00 00 02 b0 08 15 00 00 40 00 00 02 e4 80 15 00 00 40 00 00 02 6f 0a 15 00 00 40 00 00 02 e4 80 15 00 00 40 00 00 02 65 00 05 00 00 00 00 00 01 38 39 00 00 40 00 00 06 f0 55 aa 52 08 00 39 00 00 40 00 00 02 6f 01 39 00 00 00 00 00 02 be 45];
                mi,mdss-dsi-doze-lbm-command-state = "dsi_hs_mode";
                mi,mdss-dsi-doze-lbm-command = [39 00 00 40 00 00 06 f0 55 aa 52 08 02 15 00 00 00 00 00 02 cc 00 39 00 00 40 00 00 06 f0 55 aa 52 08 00 15 00 00 40 00 00 02 6f 01 15 00 00 00 00 00 02 be 41 39 00 00 40 00 00 07 51 00 00 00 00 01 55 39 00 00 40 00 00 06 f0 55 aa 52 08 01 15 00 00 40 00 00 02 6f 02 15 00 00 40 00 00 02 b0 00 15 00 00 40 00 00 02 e4 90 15 00 00 40 00 00 02 6f 0a 15 00 00 40 00 00 02 e4 90 05 00 00 40 00 00 01 39 15 00 00 00 00 00 02 65 01];
                mi,mdss-dsi-doze-hbm-command-state = "dsi_hs_mode";
                mi,mdss-dsi-doze-hbm-command = [39 00 00 40 00 00 06 f0 55 aa 52 08 02 15 00 00 00 00 00 02 cc 00 39 00 00 40 00 00 06 f0 55 aa 52 08 00 15 00 00 40 00 00 02 6f 01 15 00 00 00 00 00 02 be 41 39 00 00 40 00 00 07 51 00 00 00 00 0f ff 39 00 00 40 00 00 06 f0 55 aa 52 08 01 15 00 00 40 00 00 02 6f 02 15 00 00 40 00 00 02 b0 00 15 00 00 40 00 00 02 e4 90 15 00 00 40 00 00 02 6f 0a 15 00 00 40 00 00 02 e4 90 05 00 00 40 00 00 01 39 15 00 00 00 00 00 02 65 01];
                mi,mdss-dsi-flat-mode-off-sec-command-state = "dsi_hs_mode";
                mi,mdss-dsi-flat-mode-off-sec-command = [39 00 00 40 00 00 06 f0 55 aa 52 08 02 15 00 00 00 00 00 02 cc 00];
                mi,mdss-dsi-flat-mode-off-command-state = "dsi_hs_mode";
                mi,mdss-dsi-flat-mode-off-command = <0x15000040 0x22f 0x150000 0x40000002 0x5f011500 0x400000 0x2260015 0x4000 0x28b00 0x39000040 0x6f0 0x55aa5208 0x150000 0x40000002 0x6f031500 0x400000 0x2c01015 0x4000 0x26f31 0x15000040 0x2df 0x20390000 0x40000006 0xf055aa52 0x8021500 0x400000 0x2cc3015 0x14 0x2ce01>;
                mi,mdss-dsi-flat-mode-on-sec-command-state = "dsi_hs_mode";
                mi,mdss-dsi-flat-mode-on-sec-command = [39 00 00 40 00 00 06 f0 55 aa 52 08 02 15 00 00 00 00 00 02 cc 00];
                mi,mdss-dsi-flat-mode-on-command-state = "dsi_hs_mode";
                mi,mdss-dsi-flat-mode-on-command = <0x15000040 0x22f 0x150000 0x40000002 0x5f001500 0x400000 0x2260215 0x4000 0x28b00 0x39000040 0x6f0 0x55aa5208 0x150000 0x40000002 0x6f031500 0x400000 0x2c03215 0x4000 0x26f31 0x15000040 0x2df 0x22390000 0x40000006 0xf055aa52 0x8021500 0x400000 0x2cc3015 0x14 0x2ce01>;
                mi,mdss-flat-status-control-lhbm-gamma-cfg = <0x22 0x20>;
                mi,mdss-flat-status-control-gamma-cfg = <0x32 0x10>;
                qcom,mdss-dsc-block-prediction-enable;
                qcom,mdss-dsc-bit-per-pixel = <0x08>;
                qcom,mdss-dsc-bit-per-component = <0x0a>;
                qcom,mdss-dsc-slice-per-pkt = <0x02>;
                qcom,mdss-dsc-slice-width = <0x2d0>;
                qcom,mdss-dsc-slice-height = <0x20>;
                qcom,mdss-dsc-scr-version = <0x00>;
                qcom,mdss-dsc-version = <0x12>;
                qcom,compression-mode = "dsc";
                qcom,mdss-dsi-nolp-command-state = "dsi_hs_mode";
                qcom,mdss-dsi-nolp-command = [39 00 00 40 00 00 06 f0 55 aa 52 08 02 15 00 00 00 00 00 02 cc 00 39 00 00 40 00 00 03 51 00 00 39 00 00 40 00 00 06 f0 55 aa 52 08 01 15 00 00 40 00 00 02 6f 02 15 00 00 40 00 00 02 b0 08 15 00 00 40 00 00 02 e4 80 15 00 00 40 00 00 02 6f 0a 15 00 00 40 00 00 02 e4 80 15 00 00 40 00 00 02 65 00 05 00 00 00 00 00 01 38 39 00 00 40 00 00 06 f0 55 aa 52 08 00 39 00 00 40 00 00 02 6f 01 39 00 00 00 00 00 02 be 45];
                qcom,mdss-dsi-timing-switch-command-state = "dsi_hs_mode";
                qcom,mdss-dsi-timing-switch-command-update = <0xc0 0x04 0x01 0xdf 0x06 0x01>;
                qcom,mdss-dsi-timing-switch-command = [15 00 00 40 00 00 02 2f 00 15 00 00 40 00 00 02 8b 00 39 00 00 40 00 00 06 f0 55 aa 52 08 00 15 00 00 40 00 00 02 6f 03 15 00 00 40 00 00 02 c0 10 15 00 00 40 00 00 02 6f 31 15 00 00 40 00 00 02 df 20 39 00 00 40 00 00 06 f0 55 aa 52 08 02 15 00 00 40 00 00 02 cc 30 15 00 00 00 00 00 02 ce 01];
                qcom,mdss-dsi-off-command-state = "dsi_lp_mode";
                qcom,mdss-dsi-on-command-state = "dsi_lp_mode";
                qcom,mdss-dsi-off-command = [39 00 00 00 14 00 02 28 00 39 00 00 00 64 00 02 10 00];
                qcom,mdss-dsi-on-command = [39 00 00 40 00 00 06 f0 55 aa 52 08 00 15 00 00 40 00 00 02 6f 1a 15 00 00 00 00 00 02 c2 00 39 00 00 40 00 00 06 f0 55 aa 52 08 01 15 00 00 40 00 00 02 6f 0e 15 00 00 40 00 00 02 b4 1f 39 00 00 40 00 00 05 ff aa 55 a5 80 15 00 00 40 00 00 02 6f 02 15 00 00 00 00 00 02 f5 10 39 00 00 40 00 00 06 f0 55 aa 52 08 01 39 00 00 00 00 00 03 b1 06 06 39 00 00 40 00 00 06 f0 55 aa 52 08 01 15 00 00 40 00 00 02 6f 01 15 00 00 40 00 00 02 c4 e3 39 00 00 40 00 00 05 ff aa 55 a5 80 15 00 00 40 00 00 02 6f 18 15 00 00 00 00 00 02 f8 19 39 00 00 40 00 00 06 f0 55 aa 52 08 01 15 00 00 40 00 00 02 6f 01 39 00 00 00 00 00 04 c5 0b 0b 0b 39 00 00 40 00 00 06 f0 55 aa 52 08 04 15 00 00 00 00 00 02 c0 20 39 00 00 40 00 00 06 f0 55 aa 52 08 00 15 00 00 40 00 00 02 6f 20 39 00 00 40 00 00 09 c6 55 55 55 55 55 55 55 55 39 00 00 40 00 00 05 ff aa 55 a5 80 15 00 00 40 00 00 02 6f 1b 15 00 00 00 00 00 02 f4 55 15 00 00 40 00 00 02 6f 19 15 00 00 00 00 00 02 f2 00 39 00 00 40 00 00 05 ff aa 55 a5 81 15 00 00 40 00 00 02 6f 18 15 00 00 00 00 00 02 fb 04 39 00 00 40 00 00 05 ff aa 55 a5 81 15 00 00 40 00 00 02 6f 07 15 00 00 00 00 00 02 fc 08 39 00 00 40 00 00 05 2a 00 00 05 9f 39 00 00 00 00 00 05 2b 00 00 0c 7f 15 00 00 40 00 00 02 90 03 39 00 00 00 00 00 13 91 ab a8 00 20 d2 00 02 86 03 5e 00 0a 03 5b 02 63 10 f0 15 00 00 40 00 00 02 35 00 15 00 00 00 00 00 02 5a 01 39 00 00 40 00 00 06 f0 55 aa 52 08 01 39 00 00 40 00 00 06 d2 00 00 00 00 15 15 00 00 40 00 00 02 6f 05 39 00 00 40 00 00 04 d2 01 00 00 15 00 00 40 00 00 02 6f 0e 39 00 00 40 00 00 06 d2 00 00 10 13 32 39 00 00 40 00 00 0b e4 80 03 00 00 00 00 00 00 00 33 15 00 00 40 00 00 02 6f 0a 39 00 00 00 00 00 07 e4 80 03 00 10 00 53 39 00 00 00 00 00 05 3b 00 18 00 10 15 00 00 40 00 00 02 53 20 39 00 00 40 00 00 07 51 00 00 0f ff 0f ff 15 00 00 40 00 00 02 9c 01 15 00 00 00 00 00 02 2c 00 15 00 00 40 00 00 02 2f 00 15 00 00 40 00 00 02 5f 01 15 00 00 40 00 00 02 26 00 15 00 00 40 00 00 02 8b 00 39 00 00 40 00 00 06 f0 55 aa 52 08 00 15 00 00 40 00 00 02 6f 03 15 00 00 40 00 00 02 c0 10 15 00 00 40 00 00 02 6f 31 15 00 00 40 00 00 02 df 20 39 00 00 40 00 00 06 f0 55 aa 52 08 02 15 00 00 40 00 00 02 cc 30 15 00 00 40 14 00 02 ce 01 15 00 00 00 00 00 02 cc 00 39 00 00 40 00 00 06 f0 55 aa 52 08 01 39 00 00 40 00 00 0c c3 90 04 20 13 ff 00 04 20 0e ff 00 15 00 00 40 00 00 02 6f 0b 39 00 00 40 00 00 07 c3 06 30 1d 06 67 14 15 00 00 40 00 00 02 6f 11 39 00 00 40 00 00 07 c3 06 30 1d 06 67 14 15 00 00 40 00 00 02 6f 17 39 00 00 40 00 00 07 c3 06 30 1d 06 67 14 15 00 00 40 00 00 02 6f 1d 39 00 00 40 00 00 07 c3 06 30 1d 06 67 14 15 00 00 40 00 00 02 6f 23 39 00 00 00 00 00 07 c3 06 30 1d 06 67 14 39 00 00 40 00 00 06 f0 55 aa 52 08 00 15 00 00 40 00 00 02 6f 01 15 00 00 00 00 00 02 be 45 15 00 00 40 00 00 02 6f 05 15 00 00 00 00 00 02 be 88 39 00 00 40 00 00 06 f0 55 aa 52 08 00 15 00 00 40 00 00 02 6f 07 39 00 00 40 00 00 05 b5 2a 1e 00 32 39 00 00 40 00 00 1a b7 40 40 41 42 43 44 45 46 47 48 49 4a 4b 4c 4d 4e 4f 50 51 51 51 51 51 51 51 15 00 00 40 00 00 02 6f 19 39 00 00 40 00 00 0d b7 17 88 99 aa bb cc dd ee ff ff ff ff 15 00 00 40 00 00 02 6f 25 39 00 00 00 00 00 19 b7 ba ff 77 ef 67 df 57 cf 47 bf 37 af 27 9f 17 8f 07 7f ff ff ff ff ff ff 39 00 00 40 00 00 06 f0 55 aa 52 08 07 15 00 00 00 00 00 02 c0 b1 05 00 00 00 78 00 02 11 00 05 00 00 00 00 00 02 29 00 39 00 00 40 00 00 06 f0 55 aa 52 08 04 15 00 00 40 00 00 02 6f 16 15 00 00 40 00 00 02 d2 19 15 00 00 40 00 00 02 6f 16 15 00 00 40 00 00 02 d4 18 15 00 00 40 00 00 02 6f 2f 15 00 00 40 00 00 02 d2 28 15 00 00 40 00 00 02 6f 2f 15 00 00 40 00 00 02 d4 27 15 00 00 40 00 00 02 6f 48 15 00 00 40 00 00 02 d2 18 15 00 00 40 00 00 02 6f 48 15 00 00 00 00 00 02 d4 17];
                qcom,mdss-mdp-transfer-time-us = <0x1c84>;
                qcom,mdss-dsi-panel-jitter = <0x05 0x01>;
                qcom,mdss-dsi-panel-clockrate = <0x47868c00>;
                qcom,mdss-dsi-v-bottom-border = <0x00>;
                qcom,mdss-dsi-v-top-border = <0x00>;
                qcom,mdss-dsi-h-right-border = <0x00>;
                qcom,mdss-dsi-h-left-border = <0x00>;
                qcom,mdss-dsi-h-sync-pulse = <0x00>;
                qcom,mdss-dsi-v-pulse-width = <0x0e>;
                qcom,mdss-dsi-v-front-porch = <0x10>;
                qcom,mdss-dsi-v-back-porch = <0x06>;
                qcom,mdss-dsi-h-sync-skew = <0x00>;
                qcom,mdss-dsi-h-pulse-width = <0x0c>;
                qcom,mdss-dsi-h-back-porch = <0x08>;
                qcom,mdss-dsi-h-front-porch = <0x08>;
                qcom,mdss-dsi-panel-height = <0xc80>;
                qcom,mdss-dsi-panel-width = <0x5a0>;
                qcom,mdss-dsi-panel-framerate = <0x78>;
                qcom,mdss-dsi-cmd-mode;
            };
        };
    };
};
